# ESP32S31_RADIO register map
Vendor: Espressif; Series: ESP32-S31; File version: 3.52
Registers are 32-bit, read-write, no defined reset value unless marked. A register's access mark holds for its fields unless they carry their own. Offsets are from the block's base; [hi:lo] are bit positions; {n}, {i} and the like mark numbered series; 'fields as' and 'values as' point back to an identical list; <NAME> marks a mode.

## BLUETOOTH_CONTROLLER_CORE — Bluetooth controller-core register view grouped by runtime responsibility rather than vendor object boundaries. It owns task-side scheduler, sleep-timer, controller initialization, memory-list, scan-snapshot and ISO-coexistence state reached through the 0x20101000 physical block. Interrupt programming, enable/status, acknowledgement and fault diagnostics belong exclusively to BLUETOOTH_INTERRUPT_BANK; the two scheduler words accessed by the hard handler belong exclusively to BLUETOOTH_SCHEDULER_INTERRUPT_RUNTIME.
Base 0x20101000
0x00 SCHEDULER_CONTROL wo — Project-assigned name. Final hardware command of scheduler run. The complete current run prologue always returns zero after dynamic IRQ preparation and synchronous broker publication, so the following complete leaf writes finite image 1; the same-chip named predecessor identifies the composed operation as r_btdm_sched_run.
  [31:0] COMMAND — Project-assigned name. Complete final scheduler hardware-run command image.
    on write: 1=RUN (Request scheduler execution after a hardware-list head publication.)
0x04 SCHEDULER_LIFECYCLE_REQUEST wo — Project-assigned name. The scheduler lifecycle function reached from both BTDM task disable and shutdown writes complete image 1 only after its initial BUSY gate, dynamic interrupt masking, synchronous scheduler-run source disable and command-readiness wait. It then waits for scheduler BUSY to clear. The hardware meaning of this request remains unknown.
  [31:0] VALUE — Project-assigned name. Complete lifecycle-request image.
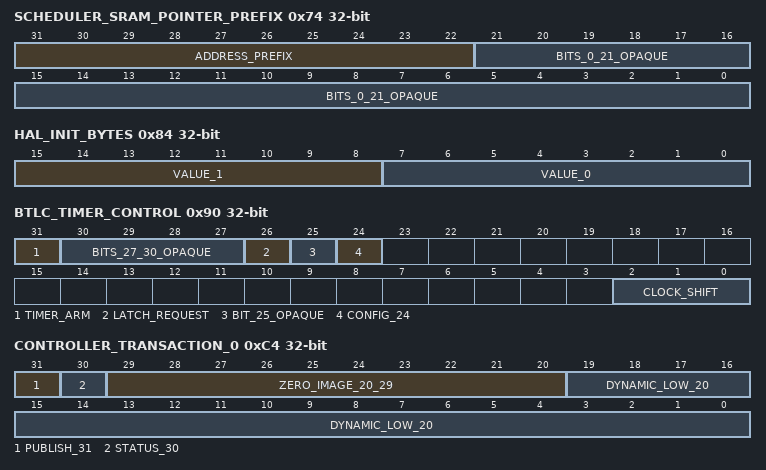
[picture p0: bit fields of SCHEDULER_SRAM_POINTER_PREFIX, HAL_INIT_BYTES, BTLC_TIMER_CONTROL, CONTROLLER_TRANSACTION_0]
0x74 SCHEDULER_SRAM_POINTER_PREFIX — Project-assigned name. Hardware initialization publishes bits 22..31 from an SRAM configuration address. The pinned scheduler list users reconstruct pointers with the constant 0x2F000000 instead; the source-124 deferred-work snapshot and the recycle dequeue path still OR this prefix with compressed 20-bit pointer values shifted left by two.
  [31:22] ADDRESS_PREFIX — Project-assigned name.
  [21:0] BITS_0_21_OPAQUE — Opaque: meaning not established. Full HAL initialization writes zero to the low 22 unassigned positions.
0x80 CONTROLLER_AUXILIARY_POINTER ro — Project-assigned name. Three observed controller paths read the low twenty bits after consulting SCHEDULER_STATE and reconstruct an SRAM address as 0x2F000000 | (value << 2). The relationship between the two pointer sources remains unknown.
  [19:0] COMPRESSED_SRAM_POINTER — Project-assigned name.
0x84 HAL_INIT_BYTES — Project-assigned name. Complete BTDM HAL initialization replaces bytes zero and one with two independently runtime-derived values while preserving bits 16..31. Their inner meanings remain unknown.
  [15:8] VALUE_1 — Project-assigned name.
  [7:0] VALUE_0 — Project-assigned name.
0x8C BTLC_TIMER_CC_0 wo — Project-assigned name. Timer compare slot 0 of r_obh_link_btlc_timer_cc_set; controller initialization writes zero.
  [31:0] VALUE — Project-assigned name.
0x90 BTLC_TIMER_CONTROL — Project-assigned name. BT link-controller timer control. Bits 2:0 are the clock shift: r_obh_link_btlc_fre_get returns the crystal frequency in kHz shifted right by them. Initialization also programs bit 24; callers set bit 26 and wait for hardware to clear it before reading the capture words; the timer-programming path sets bit 31.
  [31] TIMER_ARM — Project-assigned name.
  [30:27] BITS_27_30_OPAQUE — Opaque: meaning not established. HAL initialization clears these unassigned positions together with the complete high-byte reset.
  [26] LATCH_REQUEST — Project-assigned name.
  [25] BIT_25_OPAQUE — Opaque: meaning not established. HAL initialization clears this unassigned position together with the complete high-byte reset.
  [24] CONFIG_24 — Project-assigned name.
  [2:0] CLOCK_SHIFT — Project-assigned name.
0x94 BTLC_TIMER_VALUE_0 — Project-assigned name. First of the three words r_obd_update_btlc_timer writes before BTLC_TIMER_CONTROL.TIMER_ARM.
  [31:0] VALUE — Project-assigned name.
0x98 BTLC_TIMER_VALUE_1 — Project-assigned name. Second of the three words r_obd_update_btlc_timer writes before BTLC_TIMER_CONTROL.TIMER_ARM.
  [31:0] VALUE — Project-assigned name.
0x9C BTLC_TIMER_VALUE_2 — Project-assigned name. Third of the three words r_obd_update_btlc_timer writes before BTLC_TIMER_CONTROL.TIMER_ARM.
  [31:0] VALUE — Project-assigned name.
0xAC BTLC_TIMER_CAPTURE_0 ro — Project-assigned name. First word of the timer capture r_obd_capture_btlc_timer reads after BTLC_TIMER_CONTROL.LATCH_REQUEST clears.
  [31:0] VALUE — Project-assigned name.
0xB0 BTLC_TIMER_CAPTURE_1 ro — Project-assigned name. Second word of the same timer capture.
  [31:0] VALUE — Project-assigned name.
0xB4 BTLC_TIMER_CAPTURE_2 ro — Project-assigned name. Third word of the same timer capture.
  [31:0] VALUE — Project-assigned name.
0xB8 BTLC_TIMER_CC_1 wo — Project-assigned name. Timer compare slot 1 of r_obh_link_btlc_timer_cc_set; controller initialization writes zero.
  [31:0] VALUE — Project-assigned name.
0xC4 CONTROLLER_TRANSACTION_0 — Project-assigned name. First positional controller transaction word. The observed instruction sequence publishes bit 31 together with a dynamic low-twenty-bit value, waits for bit 30, then republishes while bit 31 remains clear. The hardware operation remains unknown.
  [31] PUBLISH_31 — Project-assigned name.
  [30] STATUS_30 — Project-assigned name.
  [29:20] ZERO_IMAGE_20_29 — Project-assigned name. Every observed complete publication writes these positions as zero; no hardware-field semantics are assigned.
  [19:0] DYNAMIC_LOW_20 — Project-assigned name.
0xC8 CURRENT_TX_LINK_POINTER — Project-assigned name. Current transmit link pointer (r_obh_link_current_txlinkptr_get); software reconstructs the SRAM address as SCHEDULER_SRAM_POINTER_PREFIX | (value << 2).
  [19:0] COMPRESSED_SRAM_POINTER — Project-assigned name.
0xCC CURRENT_RX_LINK_POINTER — Project-assigned name. Current receive link pointer (r_obh_link_current_rxlinkptr_get); software reconstructs the SRAM address as SCHEDULER_SRAM_POINTER_PREFIX | (value << 2).
  [19:0] COMPRESSED_SRAM_POINTER — Project-assigned name.
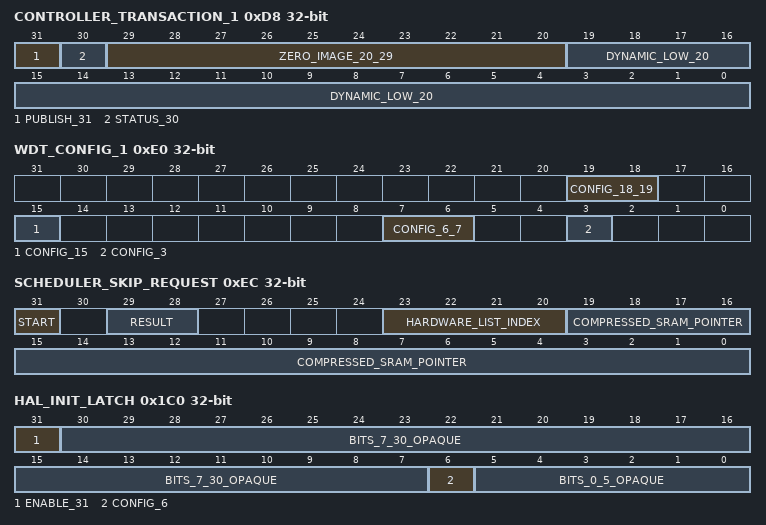
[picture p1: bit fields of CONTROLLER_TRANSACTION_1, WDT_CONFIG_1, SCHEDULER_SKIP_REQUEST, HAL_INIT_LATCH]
0xD8 CONTROLLER_TRANSACTION_1 — Project-assigned name. Second positional controller transaction word. Observed instruction sequences publish bit 31 with either a dynamic low-twenty-bit value or zero, wait for bit 30, then republish while bit 31 remains clear. The hardware operation remains unknown.
  fields as CONTROLLER_TRANSACTION_0
0xDC WDT_CONFIG_0 — Project-assigned name. First watchdog configuration word of r_obh_link_wdt_config; bit 31 is its enable. BTDM HAL initialization sets it through a fresh-read RMW.
  [31] ENABLE — Project-assigned name.
0xE0 WDT_CONFIG_1 — Project-assigned name. Second watchdog configuration word of r_obh_link_wdt_config, which packs four arguments into it. BTDM HAL initialization replaces and sets positions 3, 6, 7, 15, 18 and 19; positional groups keep the exact masks.
  [19:18] CONFIG_18_19 — Project-assigned name.
  [15] CONFIG_15 — Project-assigned name.
  [7:6] CONFIG_6_7 — Project-assigned name.
  [3] CONFIG_3 — Project-assigned name.
0xEC SCHEDULER_SKIP_REQUEST — Project-assigned name. Scheduler skip request for one listed item. The cancellation path publishes START with a zero-based hardware-list index in bits 23:20 and a compressed item pointer in bits 19:0, waits while both START and the diagnostic scheduler BUSY sample are set, takes the two-bit RESULT, and then writes zero to the complete word. The effect on the item and the meaning of each RESULT value are not established.
  [31] START — Project-assigned name.
  [29:28] RESULT — Project-assigned name.
  [23:20] HARDWARE_LIST_INDEX — Project-assigned name.
  [19:0] COMPRESSED_SRAM_POINTER — Project-assigned name.
0x1C0 HAL_INIT_LATCH — Project-assigned name. BTDM HAL initialization writes the finite complete image 0x40 and then sets bit 31 through a fresh-read RMW. Inner semantics remain unknown.
  [31] ENABLE_31 — Project-assigned name.
  [30:7] BITS_7_30_OPAQUE — Opaque: meaning not established. The initial complete HAL write clears these unassigned positions.
  [6] CONFIG_6 — Project-assigned name.
  [5:0] BITS_0_5_OPAQUE — Opaque: meaning not established. The initial complete HAL write clears these unassigned positions.
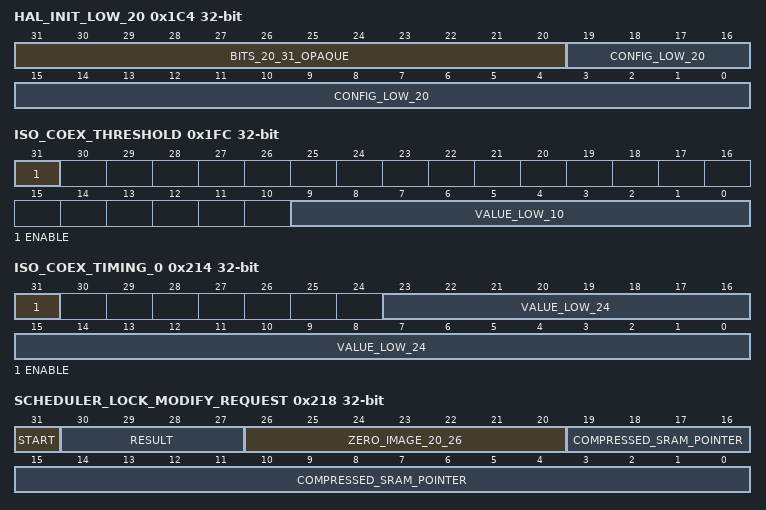
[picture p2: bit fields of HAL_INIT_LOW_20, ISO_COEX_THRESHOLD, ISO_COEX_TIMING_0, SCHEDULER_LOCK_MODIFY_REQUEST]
0x1C4 HAL_INIT_LOW_20 wo — Project-assigned name. BTDM HAL initialization writes the finite complete image 0x000FFFFF. Inner semantics remain unknown.
  [31:20] BITS_20_31_OPAQUE — Opaque: meaning not established. The complete HAL write clears the unassigned high positions.
  [19:0] CONFIG_LOW_20 — Project-assigned name.
0x1F0 GPIO_DIAG_ARGUMENT_1 wo — Project-assigned name. Second argument of r_obh_link_gpio_diag_set. Complete BLE PHY initialization writes the whole-word image 0x55.
  [31:0] VALUE — Project-assigned name.
0x1F4 ISO_COEX_ENABLE — Project-assigned name. ISO coexistence initialization sets bit 0; deinitialization clears it.
  [0] ENABLE — Project-assigned name.
0x1F8 ISO_COEX_CONTROL_0 — Project-assigned name. ISO coexistence initialization sets bit 0. Inner control semantics remain unknown.
  [0] ENABLE_0 — Project-assigned name.
0x1FC ISO_COEX_THRESHOLD — Project-assigned name. ISO coexistence initialization writes low ten-bit value 100 and then sets bit 31.
  [31] ENABLE — Project-assigned name.
  [9:0] VALUE_LOW_10 — Project-assigned name.
0x200 ISO_COEX_CONTROL_1 — Project-assigned name. ISO coexistence initialization sets bit 0. Inner control semantics remain unknown.
  [0] ENABLE_0 — Project-assigned name.
0x204 WORD_0204_OPAQUE — Opaque: meaning not established. Complete operational functions independently set and clear bit zero through fresh-read RMW operations. The scheduler cancellation path sets bit zero after publishing its hardware-list index in WORD_036C_OPAQUE bits 7:4 and acknowledging interrupt source 7, waits on WORD_0324_OPAQUE and WORD_0208_OPAQUE, and clears bit zero after its skip requests. The hardware effect of bit zero is not established.
  [0] CONTROL_0 — Project-assigned name.
0x208 WORD_0208_OPAQUE ro — Opaque: meaning not established. Two complete operational functions, the scheduler cancellation paths, consume bit zero as the second wait predicate after setting WORD_0204_OPAQUE bit zero. They continue waiting while this bit is one and the diagnostic scheduler BUSY sample is set. The remaining bits and the hardware meaning of bit zero are unknown.
  [0] STATUS_0 — Project-assigned name.
0x20C ISO_COEX_STATE_0 — Project-assigned name. ISO coexistence initialization and deinitialization write the complete zero image.
  [31:0] VALUE — Project-assigned name.
0x210 ISO_COEX_STATE_1 — Project-assigned name. ISO coexistence initialization and deinitialization write the complete zero image.
  [31:0] VALUE — Project-assigned name.
0x214 ISO_COEX_TIMING_0 — Project-assigned name. ISO coexistence initialization publishes a runtime-derived low 24-bit value and then sets bit 31.
  [31] ENABLE — Project-assigned name.
  [23:0] VALUE_LOW_24 — Project-assigned name.
0x218 SCHEDULER_LOCK_MODIFY_REQUEST — Project-assigned name. The scheduler insert-with-lock-modify path publishes START with a compressed SRAM pointer. Before and after publication it may progress whenever either START or the diagnostic scheduler BUSY sample is clear. When that publication wait ends it reports zero when BUSY is clear, otherwise the positional four-bit RESULT image returned in bits 30:27; this is not radio-item completion.
  [31] START — Project-assigned name.
  [30:27] RESULT — Project-assigned name.
  [26:20] ZERO_IMAGE_20_26 — Project-assigned name.
  [19:0] COMPRESSED_SRAM_POINTER — Project-assigned name.
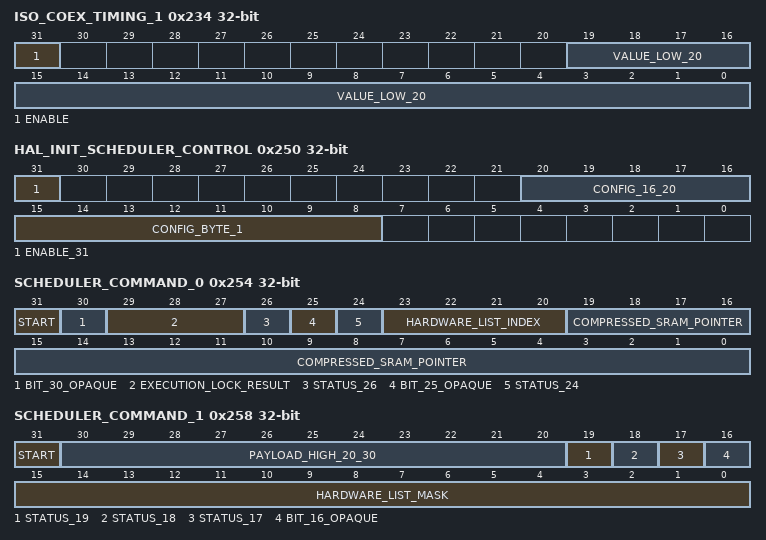
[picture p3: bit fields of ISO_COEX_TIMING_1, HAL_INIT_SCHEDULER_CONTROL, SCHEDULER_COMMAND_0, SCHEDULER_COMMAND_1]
0x234 ISO_COEX_TIMING_1 — Project-assigned name. ISO coexistence initialization publishes a runtime-derived low 20-bit value and then sets bit 31.
  [31] ENABLE — Project-assigned name.
  [19:0] VALUE_LOW_20 — Project-assigned name.
0x244 WORD_0244_OPAQUE wo — Opaque: meaning not established. Complete BLE PHY initialization writes the finite whole-word zero image. Inner hardware meaning remains unknown.
  [31:0] BITS_0_31_OPAQUE — Opaque: meaning not established.
0x248 GPIO_DIAG_CONTROL wo — Project-assigned name. GPIO diagnostic control of r_obh_link_gpio_diag_set, whose first argument replaces bits 7:4. Complete BLE PHY initialization writes the whole-word image 0x00000FFF.
  [31:0] VALUE — Project-assigned name.
0x24C WORD_024C_OPAQUE wo — Opaque: meaning not established. Complete BLE PHY initialization writes a runtime-derived complete image formed from a linked global address plus 0x40. The destination's inner hardware meaning remains unknown.
  [31:0] BITS_0_31_OPAQUE — Opaque: meaning not established.
0x250 HAL_INIT_SCHEDULER_CONTROL — Project-assigned name. BTDM HAL initialization configures byte one to 0x20, bits 16..20 to 0x10 and sets bit 31. Names remain positional because the controller meaning is not recovered.
  [31] ENABLE_31 — Project-assigned name.
  [20:16] CONFIG_16_20 — Project-assigned name.
  [15:8] CONFIG_BYTE_1 — Project-assigned name.
0x254 SCHEDULER_COMMAND_0 — Project-assigned name. First scheduler command/status transaction. The insertion execution-lock request publishes a compressed item pointer, hardware-list index and START; its finite wait observes positional status 24 and a three-bit result. Other complete paths inspect positional status 26.
  [31] START — Project-assigned name.
  [30] BIT_30_OPAQUE — Opaque: meaning not established.
  [29:27] EXECUTION_LOCK_RESULT — Project-assigned name.
  [26] STATUS_26 — Project-assigned name.
  [25] BIT_25_OPAQUE — Opaque: meaning not established.
  [24] STATUS_24 — Project-assigned name.
  [23:20] HARDWARE_LIST_INDEX — Project-assigned name.
  [19:0] COMPRESSED_SRAM_POINTER — Project-assigned name.
0x258 SCHEDULER_COMMAND_1 — Project-assigned name. Second scheduler command/status transaction. The insertion execution-modify request publishes a sixteen-list selection mask and START; its finite wait observes positional status bits 17 and 19. Other complete paths inspect positional status 18.
  [31] START — Project-assigned name.
  [30:20] PAYLOAD_HIGH_20_30 — Project-assigned name.
  [19] STATUS_19 — Project-assigned name.
  [18] STATUS_18 — Project-assigned name.
  [17] STATUS_17 — Project-assigned name.
  [16] BIT_16_OPAQUE — Opaque: meaning not established. Mode bit published with the list mask and START. Insertion publishes zero; deletion of a whole running list publishes one. Its hardware effect is not established.
  [15:0] HARDWARE_LIST_MASK — Project-assigned name.
0x25C SCHEDULER_FINISHED_LIST_STATUS ro — Project-assigned name. The scheduler worker reads the low 16 bits as the finished hardware-list mask, copies that image to SCHEDULER_FINISHED_LIST_REPORT and dispatches the mask to the BLE finished-item selector.
  [15:0] FINISHED_LIST_MASK — Project-assigned name.
0x260 SCHEDULER_FINISHED_LIST_REPORT — Project-assigned name. Before software finished-item dispatch, the scheduler worker writes the observed 16-bit SCHEDULER_FINISHED_LIST_STATUS mask as a complete zero-high image. The hardware effect of this report remains positional; other reviewed paths can clear the complete word.
  [15:0] FINISHED_LIST_MASK — Project-assigned name.
0x27C HAL_INIT_LOW_HALF — Project-assigned name. BTDM HAL initialization first clears and then sets all bits in the low halfword through two fresh-read RMW operations. Inner semantics remain unknown.
  [15:0] CONFIG_LOW_16 — Project-assigned name.
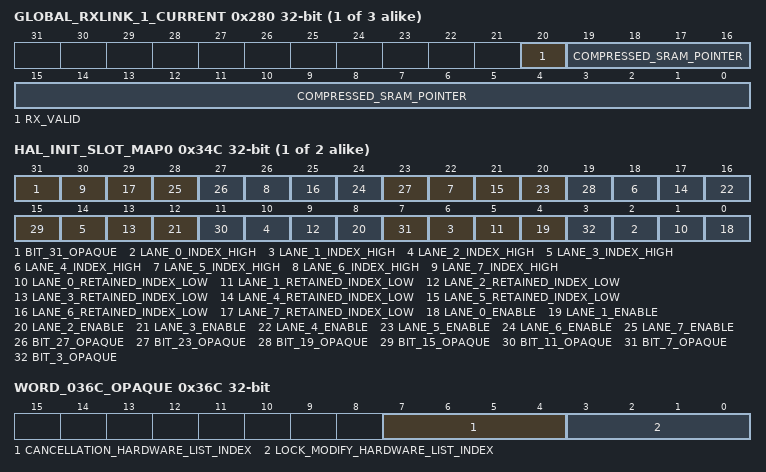
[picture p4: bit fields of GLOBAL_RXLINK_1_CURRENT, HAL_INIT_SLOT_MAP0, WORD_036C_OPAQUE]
{0x278+8i} GLOBAL_RXLINK_{i}_CURRENT (i=1..3) — Project-assigned name. Current pointer of global RX link {i} (r_obh_link_global_rxlink_curr_ptr_set) in bits 19:0 and its valid flag (r_obh_link_global_rxvalid_set) in bit 20.
  [20] RX_VALID — Project-assigned name.
  [19:0] COMPRESSED_SRAM_POINTER — Project-assigned name.
{0x27C+8i} GLOBAL_RXLINK_{i}_NEXT (i=1..3) — Project-assigned name. Next pointer of global RX link {i} (r_obh_link_global_rxlink_next_ptr_set).
  [19:0] COMPRESSED_SRAM_POINTER — Project-assigned name.
0x2A0 SCAN_HW_SNAPSHOT ro — Project-assigned name. BLE scan code reads this complete word twice until stable, converts it and stores the result in scan state. Inner hardware encoding remains unknown.
  [31:0] VALUE — Project-assigned name.
0x324 WORD_0324_OPAQUE ro — Opaque: meaning not established. The two scheduler cancellation paths read this word after setting WORD_0204_OPAQUE bit zero and wait while bit zero is clear and the diagnostic scheduler BUSY sample is set. The remaining bits and the hardware meaning of bit zero are unknown.
  [0] STATUS_0 — Project-assigned name.
{0x34C+4i} HAL_INIT_SLOT_MAP{i} (i=0..1) — Project-assigned name. The adjacent words at 0x2010134c and 0x20101350 each hold eight independently initialized four-bit lanes. For every lane, the complete BTDM HAL loop first clears bits 3:2, then sets bit 0, conditionally sets but never clears bit 1, and publishes the global-index high bit into bit 2. The hardware meaning of the words and values remains unknown.
  [31] BIT_31_OPAQUE — Opaque: meaning not established.
  [4n+2] LANE_{n}_INDEX_HIGH (n=0..7) — Project-assigned name.
  [4n+1] LANE_{n}_RETAINED_INDEX_LOW (n=0..7) — Project-assigned name.
  [4n] LANE_{n}_ENABLE (n=0..7) — Project-assigned name.
  [27] BIT_27_OPAQUE — Opaque: meaning not established.
  [23] BIT_23_OPAQUE — Opaque: meaning not established.
  [19] BIT_19_OPAQUE — Opaque: meaning not established.
  [15] BIT_15_OPAQUE — Opaque: meaning not established.
  [11] BIT_11_OPAQUE — Opaque: meaning not established.
  [7] BIT_7_OPAQUE — Opaque: meaning not established.
  [3] BIT_3_OPAQUE — Opaque: meaning not established.
0x36C WORD_036C_OPAQUE — Opaque: meaning not established. Scheduler operational word shared by several controller paths. The scheduler insert-with-lock-modify path clears, then publishes, the zero-based hardware-list index in bits 3:0 through two distinct fresh-read field updates before publishing SCHEDULER_LOCK_MODIFY_REQUEST. The scheduler cancellation path does the same for bits 7:4 before setting WORD_0204_OPAQUE bit zero. Other fields remain unassigned.
  [7:4] CANCELLATION_HARDWARE_LIST_INDEX — Project-assigned name. Zero-based hardware-list index cleared and then published by the scheduler cancellation path before it sets WORD_0204_OPAQUE bit zero.
  [3:0] LOCK_MODIFY_HARDWARE_LIST_INDEX — Project-assigned name. Zero-based hardware-list index cleared and then published by scheduler insert-with-lock-modify.
